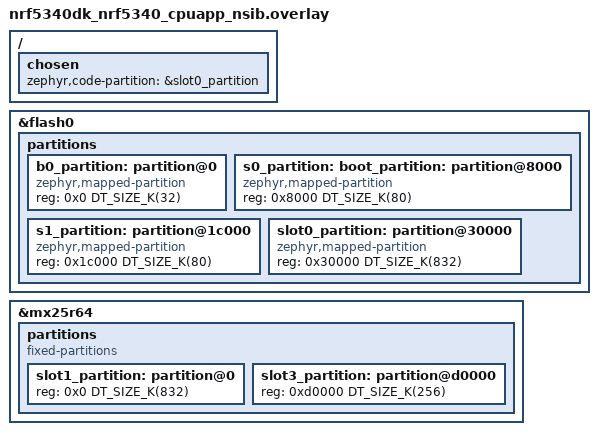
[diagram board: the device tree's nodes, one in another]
/*
 * Copyright (c) 2026 Nordic Semiconductor ASA
 *
 * SPDX-License-Identifier: LicenseRef-Nordic-5-Clause
 */

&flash0 {
	/delete-node/ partitions;

	partitions {
		ranges;
		#address-cells = <1>;
		#size-cells = <1>;

		b0_partition: partition@0 {
			compatible = "zephyr,mapped-partition";
			reg = <0x0 DT_SIZE_K(32)>;
		};

		s0_partition: boot_partition: partition@8000 {
			compatible = "zephyr,mapped-partition";
			reg = <0x8000 DT_SIZE_K(80)>;
		};

		s1_partition: partition@1c000 {
			compatible = "zephyr,mapped-partition";
			reg = <0x1c000 DT_SIZE_K(80)>;
		};

		slot0_partition: partition@30000 {
			compatible = "zephyr,mapped-partition";
			reg = <0x30000 DT_SIZE_K(832)>;
		};
	};
};

&mx25r64 {
	status = "okay";

	partitions {
		compatible = "fixed-partitions";
		#address-cells = <1>;
		#size-cells = <1>;

		slot1_partition: partition@0 {
			reg = <0x0 DT_SIZE_K(832)>;
		};

		slot3_partition: partition@d0000 {
			reg = <0xd0000 DT_SIZE_K(256)>;
		};
	};
};

/ {
	chosen {
		zephyr,code-partition = &slot0_partition;
	};
};
